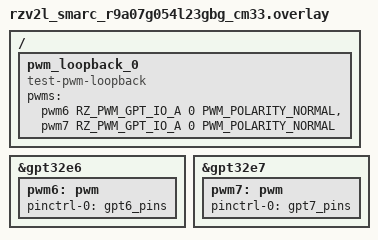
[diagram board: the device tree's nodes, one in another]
/*
 * Copyright (c) 2025 Renesas Electronics Corporation
 *
 * SPDX-License-Identifier: Apache-2.0
 */

#include <zephyr/dt-bindings/pwm/pwm.h>
#include <zephyr/dt-bindings/pwm/renesas_rz_pwm.h>

/ {
	pwm_loopback_0 {
		compatible = "test-pwm-loopback";
		pwms = <&pwm6 RZ_PWM_GPT_IO_A 0 PWM_POLARITY_NORMAL>,
		       <&pwm7 RZ_PWM_GPT_IO_A 0 PWM_POLARITY_NORMAL>;
	};
};

&gpt32e6 {
	status = "okay";

	pwm6: pwm {
		status = "okay";
		pinctrl-0 = <&gpt6_pins>;
		pinctrl-names = "default";
	};
};

&gpt32e7 {
	status = "okay";

	pwm7: pwm {
		status = "okay";
		pinctrl-0 = <&gpt7_pins>;
		pinctrl-names = "default";
	};
};
